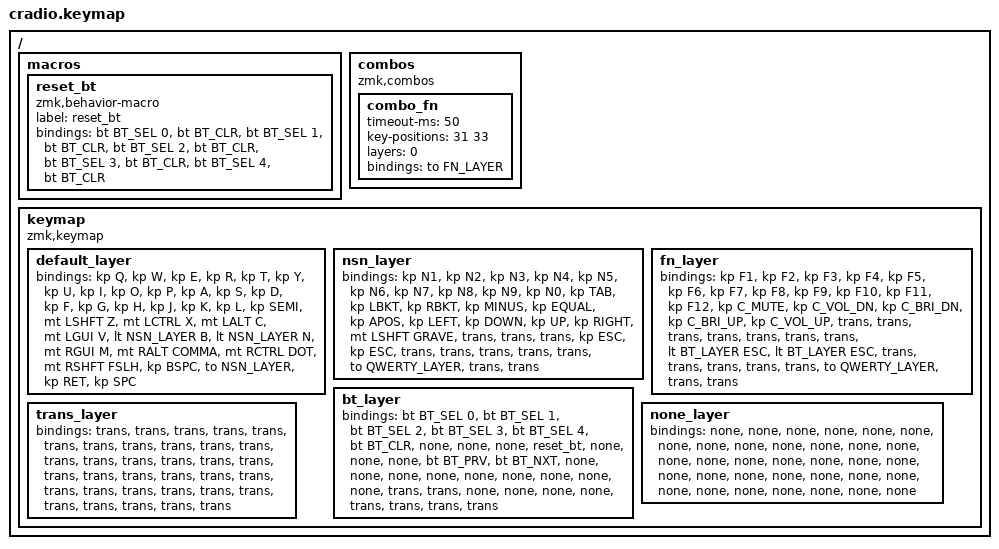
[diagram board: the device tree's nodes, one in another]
/*
 * Copyright (c) 2020 The ZMK Contributors
 *
 * SPDX-License-Identifier: MIT
 */

#include <behaviors.dtsi>
#include <dt-bindings/zmk/ext_power.h>
#include <dt-bindings/zmk/keys.h>
#include <dt-bindings/zmk/bt.h>

// LAYERS

#define QWERTY_LAYER 0
#define NSN_LAYER 1
#define FN_LAYER 2
#define BT_LAYER 3
#define TRANS_LAYER 4
#define NONE_LAYER 5

// KEY POSITIONS

// LEFT
// |  0   |  1   |  2   |  3   |  4   |
// |  10  |  11  |  12  |  13  |  14  |
// |  20  |  21  |  22  |  23  |  24  |
//                      |  30  |  31  |

//RIGHT
// |  5    |  6   |  7   |  8   |  9   |
// |  15   |  16  |  17  |  18  |  19  |
// |  25   |  26  |  27  |  28  |  29  |
// |  32   |  33  |

// ### QWERTY LAYER

// LEFT
// | Q        | W        | E       | R       | T        |
// | A        | S        | D       | F       | G        |
// | Z {SHFT} | X {CTRL} | C {ALT} | V {GUI} | B  {NSN} |
//                                 | BSPC    | NSN      |

// RIGHT
// | Y       | U       | I         | O          | P          |
// | H       | J       | K         | L          | ; :        |
// | N {NSN} | M {GUI} | , < {ALT} | . > {CTRL} | / ? {SHFT} |
// | RET     | SPACE   |           |

// ### NUM-SYM-NAV LAYER

// LEFT
// | 1 !        | 2 @ €     | 3 £ #     | 4 $       | 5 %     |
// | TAB        | [ {       | ] }       | - _       | + =     |
// | ` ~ {SHFT} | {CTRL}    | {ALT}     | {GUI}     | ESC     |
//                                      |           | QWERTY  |

// RIGHT
// | 6 ^  | 7 &   | 8 \*  | 9 (    | 0 )     |
// |  '"  | LEFT  | DOWN  | UP     | RIGHT   |
// | ESC  | {GUI} | {ALT} | {CTRL} | {SHFT}  |
// |      |       |

// ### FN LAYER

// LEFT
// | f1     | f2     | f3     | f4       | f5       |
// | f11    | f12    | C_MUTE | C_VOL_DN | C_BRI_DN |
// | {SHFT} | {CTRL} | {ALT}  | {GUI}    | ESC {BT} |     
//                            |          | QWERTY   |

// RIGHT
// | f6       | f7       | f8     | f9     | f10       |
// | C_BRI_UP | C_VOL_UP |        |        |           |
// | ESC {BT} | {GUI}    | {ALT}  | {CTRL} | {SHFT}    |
// |          |          |

// ## BT LAYER

// LEFT
// | BT_SEL 0 | BT_SEL 1 | BT_SEL 2  | BT_SEL 3  | BT_SEL 4 |
// |          |          |           | BT_PRV    | BT_NXT   |
// |          |          |           |           |          |     
//                                   |           |          |

// RIGHT
// |  CLEAR  |      |      |      | RESET  |
// |         |      |      |      |        |
// |         |      |      |      |        |
// |         |      |

/ {

    macros {
        // shutdown_keeb: shutdown_keeb {
        //     compatible = "zmk,behavior-macro";
        //     label = "shutdown_keeb";
        //     #binding-cells = <0>;
        //     bindings = <&to NONE_LAYER &kp K_SLEEP &ext_power EP_OFF>;
        // };

        reset_bt: reset_bt {
            compatible = "zmk,behavior-macro";
            label = "reset_bt";
            #binding-cells = <0>;
            bindings = <
                &bt BT_SEL 0 
                &bt BT_CLR
                &bt BT_SEL 1 
                &bt BT_CLR
                &bt BT_SEL 2 
                &bt BT_CLR
                &bt BT_SEL 3 
                &bt BT_CLR
                &bt BT_SEL 4 
                &bt BT_CLR
            >;
        };
    };

    combos {
        compatible = "zmk,combos";
        
        // combo_zzz {
        //     timeout-ms = <50>;
        //     key-positions = <24 35>;
        //     layers = <0 1 2>;
        //     bindings = <&shutdown_keeb>;
        // };

        combo_fn {
            timeout-ms = <50>;
            key-positions = <31 33>;
            layers = <0>;
            bindings = <&to FN_LAYER>;
        };
    };

    keymap {
        compatible = "zmk,keymap";

        default_layer {
            bindings = <
                &kp Q         
                &kp W         
                &kp E        
                &kp R            
                &kp T   

                /* RIGHT UPPER */
                &kp Y        
                &kp U         
                &kp I         
                &kp O        
                &kp P            

                /* LEFT MIDDLE */     
                &kp A   
                &kp S   
                &kp D   
                &kp F       
                &kp G

                /* RIGHT MIDDLE */
                &kp H        
                &kp J    
                &kp K    
                &kp L  
                &kp SEMI   

                /* LEFT LOWER */  
                &mt LSHFT Z         
                &mt LCTRL X         
                &mt LALT C        
                &mt LGUI V            
                &lt NSN_LAYER B   

                /* RIGHT LOWER */
                &lt NSN_LAYER N        
                &mt RGUI M         
                &mt RALT COMMA     
                &mt RCTRL DOT      
                &mt RSHFT FSLH         

                /* LEFT CLUSTER */
                &kp BSPC          
                &to NSN_LAYER         

                /* RIGHT CLUSTER */    
                &kp RET        
                &kp SPC      
            >;
        };

        nsn_layer {
            bindings = <
                /* LEFT UPPER */    
                &kp N1       
                &kp N2       
                &kp N3       
                &kp N4       
                &kp N5         

                /* RIGHT UPPER */
                &kp N6   
                &kp N7   
                &kp N8 
                &kp N9    
                &kp N0

                /* LEFT MIDDLE */
                &kp TAB
                &kp LBKT
                &kp RBKT
                &kp MINUS
                &kp EQUAL

                /* RIGHT MIDDLE */
                &kp APOS 
                &kp LEFT
                &kp DOWN
                &kp UP
                &kp RIGHT

                /* LEFT LOWER */
                &mt LSHFT GRAVE
                &trans
                &trans
                &trans
                &kp ESC

                /* RIGHT LOWER */
                &kp ESC
                &trans
                &trans
                &trans
                &trans

                /* LEFT CLUSTER */   
                &trans   
                &to QWERTY_LAYER      

                /* RIGHT CLUSTER */    
                &trans      
                &trans         
            >;
        };

        fn_layer {
            bindings = <
                /* LEFT UPPER */
                &kp F1 
                &kp F2        
                &kp F3 
                &kp F4 
                &kp F5

                /* RIGHT UPPER */    
                &kp F6 
                &kp F7 
                &kp F8        
                &kp F9 
                &kp F10 

                /* LEFT MIDDLE */
                &kp F11 
                &kp F12        
                &kp C_MUTE 
                &kp C_VOL_DN 
                &kp C_BRI_DN  

                /* RIGHT MIDDLE */    
                &kp C_BRI_UP 
                &kp C_VOL_UP 
                &trans        
                &trans 
                &trans 

                /* LEFT LOWER */    
                &trans   
                &trans 
                &trans   
                &trans   
                &lt BT_LAYER ESC

                /* RIGHT LOWER */    
                &lt BT_LAYER ESC
                &trans  
                &trans        
                &trans 
                &trans
                
                /* LEFT CLUSTER */               
                &trans  
                &to QWERTY_LAYER 

                /* RIGHT CLUSTER */    
                &trans   
                &trans
            >;
        };

        bt_layer {
            bindings = <
                /* LEFT UPPER */
                &bt BT_SEL 0 
                &bt BT_SEL 1        
                &bt BT_SEL 2 
                &bt BT_SEL 3 
                &bt BT_SEL 4

                /* RIGHT UPPER */    
                &bt BT_CLR 
                &none 
                &none        
                &none 
                &reset_bt 

                /* LEFT MIDDLE */
                &none 
                &none        
                &none 
                &bt BT_PRV 
                &bt BT_NXT 

                /* RIGHT MIDDLE */    
                &none 
                &none 
                &none        
                &none 
                &none 

                /* LEFT LOWER */    
                &none   
                &none 
                &none   
                &none   
                &trans

                /* RIGHT LOWER */    
                &trans 
                &none  
                &none        
                &none 
                &none
                
                /* LEFT CLUSTER */               
                &trans  
                &trans 

                /* RIGHT CLUSTER */    
                &trans   
                &trans
            >;
        };

        trans_layer {
            bindings = <
                /* LEFT UPPER */
                &trans 
                &trans        
                &trans 
                &trans 
                &trans

                /* RIGHT UPPER */    
                &trans 
                &trans 
                &trans        
                &trans 
                &trans 

                /* LEFT MIDDLE */
                &trans 
                &trans        
                &trans 
                &trans 
                &trans  

                /* RIGHT MIDDLE */    
                &trans 
                &trans        
                &trans 
                &trans 
                &trans

                /* LEFT LOWER */    
                &trans   
                &trans 
                &trans   
                &trans   
                &trans

                /* RIGHT LOWER */    
                &trans  
                &trans        
                &trans 
                &trans
                &trans
                
                /* LEFT CLUSTER */               
                &trans  
                &trans 

                /* RIGHT CLUSTER */     
                &trans
                &trans
            >;
        };

        none_layer {
            bindings = <
                /* LEFT UPPER */
                &none 
                &none        
                &none 
                &none 
                &none

                /* RIGHT UPPER */    
                &none 
                &none        
                &none 
                &none 
                &none

                /* LEFT MIDDLE */
                &none 
                &none        
                &none 
                &none 
                &none  

                /* RIGHT MIDDLE */    
                &none 
                &none        
                &none 
                &none 
                &none

                /* LEFT LOWER */     
                &none   
                &none 
                &none   
                &none   
                &none

                /* RIGHT LOWER */    
                &none  
                &none        
                &none 
                &none
                &none
                
                /* LEFT CLUSTER */               
                &none  
                &none 

                /* RIGHT CLUSTER */      
                &none
                &none
            >;
        };
    };
};
    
